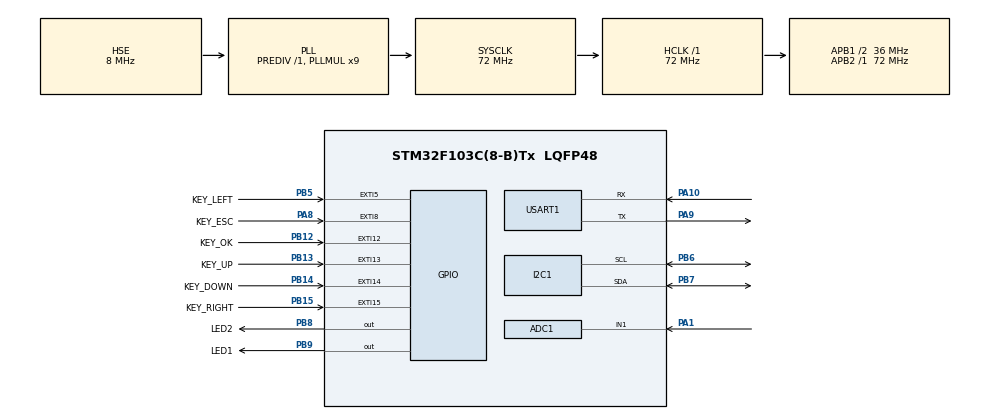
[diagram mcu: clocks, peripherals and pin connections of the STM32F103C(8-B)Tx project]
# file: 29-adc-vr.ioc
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ADC1.Channel-1\#ChannelRegularConversion=ADC_CHANNEL_TEMPSENSOR
ADC1.NbrOfConversionFlag=1
ADC1.Rank-1\#ChannelRegularConversion=1
ADC1.SamplingTime-1\#ChannelRegularConversion=ADC_SAMPLETIME_239CYCLES_5
ADC1.master=1
Dma.Request0=USART1_RX
Dma.USART1_RX.0.Direction=DMA_PERIPH_TO_MEMORY
Dma.USART1_RX.0.Instance=DMA1_Channel5
Dma.USART1_RX.0.MemDataAlignment=DMA_MDATAALIGN_BYTE
Dma.USART1_RX.0.MemInc=DMA_MINC_ENABLE
Dma.USART1_RX.0.Mode=DMA_CIRCULAR
Dma.USART1_RX.0.PeriphDataAlignment=DMA_PDATAALIGN_BYTE
Dma.USART1_RX.0.PeriphInc=DMA_PINC_DISABLE
Dma.USART1_RX.0.Priority=DMA_PRIORITY_LOW
Mcu.Family=STM32F1
Mcu.Name=STM32F103C(8-B)Tx
Mcu.Package=LQFP48
NVIC.DMA1_Channel5_IRQn=true\:0\:0\:false\:false\:true\:false\:true\:true
NVIC.EXTI15_10_IRQn=true\:0\:0\:false\:false\:true\:true\:true\:true
NVIC.EXTI9_5_IRQn=true\:0\:0\:false\:false\:true\:true\:true\:true
NVIC.PriorityGroup=NVIC_PRIORITYGROUP_4
NVIC.USART1_IRQn=true\:0\:0\:false\:false\:true\:true\:true\:true
PA1.Signal=ADCx_IN1
PA10.GPIO_PuPd=GPIO_PULLUP
PA10.Mode=Asynchronous
PA10.Signal=USART1_RX
PA8.GPIO_Label=KEY_ESC
PA8.GPIO_ModeDefaultEXTI=GPIO_MODE_IT_FALLING
PA8.GPIO_PuPd=GPIO_PULLUP
PA8.Signal=GPXTI8
PA9.Mode=Asynchronous
PA9.Signal=USART1_TX
PB12.GPIO_Label=KEY_OK
PB12.GPIO_ModeDefaultEXTI=GPIO_MODE_IT_FALLING
PB12.GPIO_PuPd=GPIO_PULLUP
PB12.Signal=GPXTI12
PB13.GPIO_Label=KEY_UP
PB13.GPIO_ModeDefaultEXTI=GPIO_MODE_IT_FALLING
PB13.GPIO_PuPd=GPIO_PULLUP
PB13.Signal=GPXTI13
PB14.GPIO_Label=KEY_DOWN
PB14.GPIO_ModeDefaultEXTI=GPIO_MODE_IT_FALLING
PB14.GPIO_PuPd=GPIO_PULLUP
PB14.Signal=GPXTI14
PB15.GPIO_Label=KEY_RIGHT
PB15.GPIO_ModeDefaultEXTI=GPIO_MODE_IT_FALLING
PB15.GPIO_PuPd=GPIO_PULLUP
PB15.Signal=GPXTI15
PB5.GPIO_Label=KEY_LEFT
PB5.GPIO_ModeDefaultEXTI=GPIO_MODE_IT_FALLING
PB5.GPIO_PuPd=GPIO_PULLUP
PB5.Signal=GPXTI5
PB6.Mode=I2C
PB6.Signal=I2C1_SCL
PB7.Mode=I2C
PB7.Signal=I2C1_SDA
PB8.GPIO_Label=LED2
PB8.PinState=GPIO_PIN_SET
PB8.Signal=GPIO_Output
PB9.GPIO_Label=LED1
PB9.PinState=GPIO_PIN_SET
PB9.Signal=GPIO_Output
PD0-OSC_IN.Mode=HSE-External-Oscillator
PD0-OSC_IN.Signal=RCC_OSC_IN
PD1-OSC_OUT.Mode=HSE-External-Oscillator
PD1-OSC_OUT.Signal=RCC_OSC_OUT
ProjectManager.HeapSize=0x200
ProjectManager.StackSize=0x400
ProjectManager.TargetToolchain=MDK-ARM V5.32
RCC.ADCPresc=RCC_ADCPCLK2_DIV6
RCC.AHBFreq_Value=72000000
RCC.APB1CLKDivider=RCC_HCLK_DIV2
RCC.APB1Freq_Value=36000000
RCC.APB1TimFreq_Value=72000000
RCC.APB2Freq_Value=72000000
RCC.APB2TimFreq_Value=72000000
RCC.HCLKFreq_Value=72000000
RCC.PLLMUL=RCC_PLL_MUL9
RCC.PLLSourceVirtual=RCC_PLLSOURCE_HSE
RCC.SYSCLKFreq_VALUE=72000000
RCC.SYSCLKSource=RCC_SYSCLKSOURCE_PLLCLK
RCC.USBFreq_Value=72000000
SH.ADCx_IN1.0=ADC1_IN1,IN1
USART1.VirtualMode=VM_ASYNC
VP_ADC1_TempSens_Input.Mode=IN-TempSens
VP_SYS_VS_ND.Mode=No_Debug
board=custom

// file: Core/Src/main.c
/* USER CODE BEGIN Header */
/**
 ******************************************************************************
 * @file           : main.c
 * @brief          : Main program body
 ******************************************************************************
 * @attention
 *
 * Copyright (c) 2025 STMicroelectronics.
 * All rights reserved.
 *
 * This software is licensed under terms that can be found in the LICENSE file
 * in the root directory of this software component.
 * If no LICENSE file comes with this software, it is provided AS-IS.
 *
 ******************************************************************************
 */
/* USER CODE END Header */
#include "main.h"
#include "adc.h"
#include "dma.h"
#include "i2c.h"
#include "usart.h"
#include "gpio.h"

/* USER CODE BEGIN Includes */
#include <stdio.h>
#include "oled.h"
/* USER CODE END Includes */

void SystemClock_Config(void);

int main(void)
{

  /* MCU Configuration--------------------------------------------------------*/

  /* Reset of all peripherals, Initializes the Flash interface and the Systick. */
  HAL_Init();

  /* Configure the system clock */
  SystemClock_Config();

  /* Initialize all configured peripherals */
  MX_GPIO_Init();
  MX_DMA_Init();
  MX_USART1_UART_Init();
  MX_ADC1_Init();
  MX_I2C1_Init();
  /* USER CODE BEGIN 2 */
  OLED_Init();  // OLED初始
  OLED_Clear(); // 清屏

  __HAL_UART_ENABLE_IT(&huart1, UART_IT_IDLE); // 开启空闲中断
  HAL_UART_Receive_DMA(&huart1, Rx1_Buf, DMA_BUF_SIZE);
  printf("ADC CPU Test\r\n");
  OLED_ShowString(10, 0, "ADC VRCPU Test", 16, 0); // 反相显示8X16字符串
  OLED_ShowString(0, 3, "VR:", 16, 0);             // 反相显示8X16字符串
  OLED_ShowString(0, 5, "CPU:", 16, 0);            // 反相显示8X16字符串
  //    LED_control(LED1, ON);
  //	HAL_GPIO_WritePin(GPIOB,GPIO_PIN_9,GPIO_PIN_RESET);

  /* USER CODE END 2 */

  /* Infinite loop */
  /* USER CODE BEGIN WHILE */
  while (1)
  {
    // LED_Test();
    // BEEP_Test();
    /* USER CODE END WHILE */

    /* USER CODE BEGIN 3 */
    ADC_VR_CPU_Test();
    // HAL_Delay(100);
  }
  /* USER CODE END 3 */
}

void SystemClock_Config(void)
{
  RCC_OscInitTypeDef RCC_OscInitStruct = {0};
  RCC_ClkInitTypeDef RCC_ClkInitStruct = {0};
  RCC_PeriphCLKInitTypeDef PeriphClkInit = {0};

  /** Initializes the RCC Oscillators according to the specified parameters
   * in the RCC_OscInitTypeDef structure.
   */
  RCC_OscInitStruct.OscillatorType = RCC_OSCILLATORTYPE_HSE;
  RCC_OscInitStruct.HSEState = RCC_HSE_ON;
  RCC_OscInitStruct.HSEPredivValue = RCC_HSE_PREDIV_DIV1;
  RCC_OscInitStruct.HSIState = RCC_HSI_ON;
  RCC_OscInitStruct.PLL.PLLState = RCC_PLL_ON;
  RCC_OscInitStruct.PLL.PLLSource = RCC_PLLSOURCE_HSE;
  RCC_OscInitStruct.PLL.PLLMUL = RCC_PLL_MUL9;
  if (HAL_RCC_OscConfig(&RCC_OscInitStruct) != HAL_OK)
  {
    Error_Handler();
  }

  /** Initializes the CPU, AHB and APB buses clocks
   */
  RCC_ClkInitStruct.ClockType = RCC_CLOCKTYPE_HCLK | RCC_CLOCKTYPE_SYSCLK | RCC_CLOCKTYPE_PCLK1 | RCC_CLOCKTYPE_PCLK2;
  RCC_ClkInitStruct.SYSCLKSource = RCC_SYSCLKSOURCE_PLLCLK;
  RCC_ClkInitStruct.AHBCLKDivider = RCC_SYSCLK_DIV1;
  RCC_ClkInitStruct.APB1CLKDivider = RCC_HCLK_DIV2;
  RCC_ClkInitStruct.APB2CLKDivider = RCC_HCLK_DIV1;

  if (HAL_RCC_ClockConfig(&RCC_ClkInitStruct, FLASH_LATENCY_2) != HAL_OK)
  {
    Error_Handler();
  }
  PeriphClkInit.PeriphClockSelection = RCC_PERIPHCLK_ADC;
  PeriphClkInit.AdcClockSelection = RCC_ADCPCLK2_DIV6;
  if (HAL_RCCEx_PeriphCLKConfig(&PeriphClkInit) != HAL_OK)
  {
    Error_Handler();
  }
}

void Error_Handler(void)
{
  __disable_irq();
  while (1)
  {
  }
}
